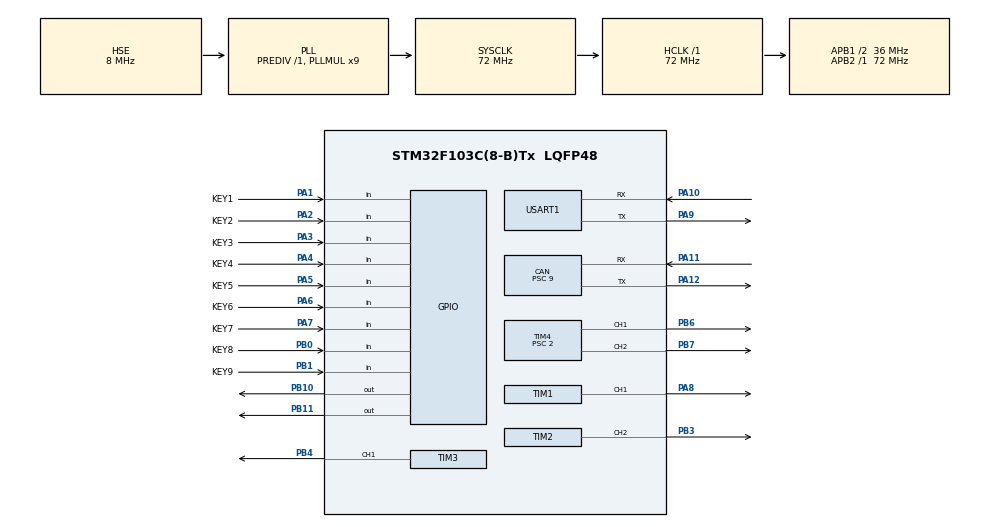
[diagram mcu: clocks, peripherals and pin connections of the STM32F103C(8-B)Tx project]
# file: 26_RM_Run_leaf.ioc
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CAN.BS2=CAN_BS2_2TQ
CAN.CalculateBaudRate=1000000
CAN.CalculateTimeBit=1000
CAN.CalculateTimeQuantum=250.0
CAN.Prescaler=9
Dma.Request0=TIM1_CH1
Dma.Request1=TIM2_CH2/CH4
Dma.Request2=TIM4_CH1
Dma.Request3=TIM4_CH2
Dma.Request4=TIM3_CH1/TRIG
Dma.TIM1_CH1.0.Direction=DMA_MEMORY_TO_PERIPH
Dma.TIM1_CH1.0.Instance=DMA1_Channel2
Dma.TIM1_CH1.0.MemDataAlignment=DMA_MDATAALIGN_HALFWORD
Dma.TIM1_CH1.0.MemInc=DMA_MINC_ENABLE
Dma.TIM1_CH1.0.Mode=DMA_CIRCULAR
Dma.TIM1_CH1.0.PeriphDataAlignment=DMA_PDATAALIGN_HALFWORD
Dma.TIM1_CH1.0.PeriphInc=DMA_PINC_DISABLE
Dma.TIM1_CH1.0.Priority=DMA_PRIORITY_HIGH
Dma.TIM2_CH2/CH4.1.Direction=DMA_MEMORY_TO_PERIPH
Dma.TIM2_CH2/CH4.1.Instance=DMA1_Channel7
Dma.TIM2_CH2/CH4.1.MemDataAlignment=DMA_MDATAALIGN_HALFWORD
Dma.TIM2_CH2/CH4.1.MemInc=DMA_MINC_ENABLE
Dma.TIM2_CH2/CH4.1.Mode=DMA_CIRCULAR
Dma.TIM2_CH2/CH4.1.PeriphDataAlignment=DMA_PDATAALIGN_HALFWORD
Dma.TIM2_CH2/CH4.1.PeriphInc=DMA_PINC_DISABLE
Dma.TIM2_CH2/CH4.1.Priority=DMA_PRIORITY_HIGH
Dma.TIM3_CH1/TRIG.4.Direction=DMA_MEMORY_TO_PERIPH
Dma.TIM3_CH1/TRIG.4.Instance=DMA1_Channel6
Dma.TIM3_CH1/TRIG.4.MemDataAlignment=DMA_MDATAALIGN_HALFWORD
Dma.TIM3_CH1/TRIG.4.MemInc=DMA_MINC_ENABLE
Dma.TIM3_CH1/TRIG.4.Mode=DMA_CIRCULAR
Dma.TIM3_CH1/TRIG.4.PeriphDataAlignment=DMA_PDATAALIGN_HALFWORD
Dma.TIM3_CH1/TRIG.4.PeriphInc=DMA_PINC_DISABLE
Dma.TIM3_CH1/TRIG.4.Priority=DMA_PRIORITY_HIGH
Dma.TIM4_CH1.2.Direction=DMA_MEMORY_TO_PERIPH
Dma.TIM4_CH1.2.Instance=DMA1_Channel1
Dma.TIM4_CH1.2.MemDataAlignment=DMA_MDATAALIGN_HALFWORD
Dma.TIM4_CH1.2.MemInc=DMA_MINC_ENABLE
Dma.TIM4_CH1.2.Mode=DMA_CIRCULAR
Dma.TIM4_CH1.2.PeriphDataAlignment=DMA_PDATAALIGN_HALFWORD
Dma.TIM4_CH1.2.PeriphInc=DMA_PINC_DISABLE
Dma.TIM4_CH1.2.Priority=DMA_PRIORITY_HIGH
Dma.TIM4_CH2.3.Direction=DMA_MEMORY_TO_PERIPH
Dma.TIM4_CH2.3.Instance=DMA1_Channel4
Dma.TIM4_CH2.3.MemDataAlignment=DMA_MDATAALIGN_HALFWORD
Dma.TIM4_CH2.3.MemInc=DMA_MINC_ENABLE
Dma.TIM4_CH2.3.Mode=DMA_CIRCULAR
Dma.TIM4_CH2.3.PeriphDataAlignment=DMA_PDATAALIGN_HALFWORD
Dma.TIM4_CH2.3.PeriphInc=DMA_PINC_DISABLE
Dma.TIM4_CH2.3.Priority=DMA_PRIORITY_HIGH
Mcu.Family=STM32F1
Mcu.Name=STM32F103C(8-B)Tx
Mcu.Package=LQFP48
NVIC.DMA1_Channel1_IRQn=true\:0\:0\:false\:false\:true\:false\:true\:true
NVIC.DMA1_Channel2_IRQn=true\:0\:0\:false\:false\:true\:false\:true\:true
NVIC.DMA1_Channel4_IRQn=true\:0\:0\:false\:false\:true\:false\:true\:true
NVIC.DMA1_Channel6_IRQn=true\:0\:0\:false\:false\:true\:false\:true\:true
NVIC.DMA1_Channel7_IRQn=true\:0\:0\:false\:false\:true\:false\:true\:true
NVIC.PriorityGroup=NVIC_PRIORITYGROUP_4
PA1.GPIO_Label=KEY1
PA1.GPIO_PuPd=GPIO_PULLUP
PA1.Signal=GPIO_Input
PA10.Mode=Asynchronous
PA10.Signal=USART1_RX
PA11.Mode=CAN_Activate
PA11.Signal=CAN_RX
PA12.Mode=CAN_Activate
PA12.Signal=CAN_TX
PA13.Mode=Serial_Wire
PA13.Signal=SYS_JTMS-SWDIO
PA14.Mode=Serial_Wire
PA14.Signal=SYS_JTCK-SWCLK
PA2.GPIO_Label=KEY2
PA2.GPIO_PuPd=GPIO_PULLUP
PA2.Signal=GPIO_Input
PA3.GPIO_Label=KEY3
PA3.GPIO_PuPd=GPIO_PULLUP
PA3.Signal=GPIO_Input
PA4.GPIO_Label=KEY4
PA4.GPIO_PuPd=GPIO_PULLUP
PA4.Signal=GPIO_Input
PA5.GPIO_Label=KEY5
PA5.GPIO_PuPd=GPIO_PULLUP
PA5.Signal=GPIO_Input
PA6.GPIO_Label=KEY6
PA6.GPIO_PuPd=GPIO_PULLUP
PA6.Signal=GPIO_Input
PA7.GPIO_Label=KEY7
PA7.GPIO_PuPd=GPIO_PULLUP
PA7.Signal=GPIO_Input
PA8.Signal=S_TIM1_CH1
PA9.Mode=Asynchronous
PA9.Signal=USART1_TX
PB0.GPIO_Label=KEY8
PB0.GPIO_PuPd=GPIO_PULLUP
PB0.Signal=GPIO_Input
PB1.GPIO_Label=KEY9
PB1.GPIO_PuPd=GPIO_PULLUP
PB1.Signal=GPIO_Input
PB10.Signal=GPIO_Output
PB11.Signal=GPIO_Output
PB3.Signal=S_TIM2_CH2
PB4.Signal=S_TIM3_CH1
PB6.Signal=S_TIM4_CH1
PB7.Signal=S_TIM4_CH2
PD0-OSC_IN.Mode=HSE-External-Oscillator
PD0-OSC_IN.Signal=RCC_OSC_IN
PD1-OSC_OUT.Mode=HSE-External-Oscillator
PD1-OSC_OUT.Signal=RCC_OSC_OUT
ProjectManager.HeapSize=0x200
ProjectManager.StackSize=0x400
ProjectManager.TargetToolchain=STM32CubeIDE
RCC.AHBFreq_Value=72000000
RCC.APB1CLKDivider=RCC_HCLK_DIV2
RCC.APB1Freq_Value=36000000
RCC.APB1TimFreq_Value=72000000
RCC.APB2Freq_Value=72000000
RCC.APB2TimFreq_Value=72000000
RCC.HCLKFreq_Value=72000000
RCC.PLLMUL=RCC_PLL_MUL9
RCC.PLLSourceVirtual=RCC_PLLSOURCE_HSE
RCC.SYSCLKFreq_VALUE=72000000
RCC.SYSCLKSource=RCC_SYSCLKSOURCE_PLLCLK
RCC.USBFreq_Value=72000000
SH.S_TIM1_CH1.0=TIM1_CH1,PWM Generation1 CH1
SH.S_TIM2_CH2.0=TIM2_CH2,PWM Generation2 CH2
SH.S_TIM3_CH1.0=TIM3_CH1,PWM Generation1 CH1
SH.S_TIM4_CH1.0=TIM4_CH1,PWM Generation1 CH1
SH.S_TIM4_CH2.0=TIM4_CH2,PWM Generation2 CH2
TIM1.Channel-PWM\ Generation1\ CH1=TIM_CHANNEL_1
TIM1.Period=29
TIM1.Prescaler=2
TIM2.Channel-PWM\ Generation2\ CH2=TIM_CHANNEL_2
TIM2.Period=29
TIM2.Prescaler=2
TIM3.Channel-PWM\ Generation1\ CH1=TIM_CHANNEL_1
TIM3.Period=29
TIM3.Prescaler=2
TIM4.Channel-PWM\ Generation1\ CH1=TIM_CHANNEL_1
TIM4.Channel-PWM\ Generation2\ CH2=TIM_CHANNEL_2
TIM4.Period=29
TIM4.Prescaler=2
USART1.VirtualMode=VM_ASYNC
VP_TIM1_VS_ClockSourceINT.Mode=Internal
VP_TIM2_VS_ClockSourceINT.Mode=Internal
VP_TIM3_VS_ClockSourceINT.Mode=Internal
VP_TIM4_VS_ClockSourceINT.Mode=Internal
board=custom

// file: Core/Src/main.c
/* USER CODE BEGIN Header */
/**
  ******************************************************************************
  * @file           : main.c
  * @brief          : Main program body
  ******************************************************************************
  * @attention
  *
  * Copyright (c) 2026 STMicroelectronics.
  * All rights reserved.
  *
  * This software is licensed under terms that can be found in the LICENSE file
  * in the root directory of this software component.
  * If no LICENSE file comes with this software, it is provided AS-IS.
  *
  ******************************************************************************
  */
/* USER CODE END Header */
#include "main.h"
#include "can.h"
#include "dma.h"
#include "tim.h"
#include "usart.h"
#include "gpio.h"

/* USER CODE BEGIN Includes */
#include "deliver.h"
#include "light.h"

/* USER CODE END Includes */

void SystemClock_Config(void);

int main(void)
{

  /* MCU Configuration--------------------------------------------------------*/

  /* Reset of all peripherals, Initializes the Flash interface and the Systick. */
  HAL_Init();

  /* Configure the system clock */
  SystemClock_Config();

  /* Initialize all configured peripherals */
  MX_GPIO_Init();
  MX_DMA_Init();
  MX_TIM1_Init();
  MX_CAN_Init();
  MX_USART1_UART_Init();
  MX_TIM2_Init();
  MX_TIM4_Init();
  MX_TIM3_Init();
  /* USER CODE BEGIN 2 */
  can_filter_init(); // 初始化CAN过滤器
  Light_Init(RedState); // 初始化LED为红色阵营
  /* USER CODE END 2 */

  /* Infinite loop */
  /* USER CODE BEGIN WHILE */
  while (1)
  {
    led_update(); // 更新LED状态
    HAL_Delay(100); // 小延时，避免过于频繁更新
    /* USER CODE END WHILE */

  }
}

void SystemClock_Config(void)
{
  RCC_OscInitTypeDef RCC_OscInitStruct = {0};
  RCC_ClkInitTypeDef RCC_ClkInitStruct = {0};

  /** Initializes the RCC Oscillators according to the specified parameters
  * in the RCC_OscInitTypeDef structure.
  */
  RCC_OscInitStruct.OscillatorType = RCC_OSCILLATORTYPE_HSE;
  RCC_OscInitStruct.HSEState = RCC_HSE_ON;
  RCC_OscInitStruct.HSEPredivValue = RCC_HSE_PREDIV_DIV1;
  RCC_OscInitStruct.HSIState = RCC_HSI_ON;
  RCC_OscInitStruct.PLL.PLLState = RCC_PLL_ON;
  RCC_OscInitStruct.PLL.PLLSource = RCC_PLLSOURCE_HSE;
  RCC_OscInitStruct.PLL.PLLMUL = RCC_PLL_MUL9;
  if (HAL_RCC_OscConfig(&RCC_OscInitStruct) != HAL_OK)
  {
    Error_Handler();
  }

  /** Initializes the CPU, AHB and APB buses clocks
  */
  RCC_ClkInitStruct.ClockType = RCC_CLOCKTYPE_HCLK|RCC_CLOCKTYPE_SYSCLK
                              |RCC_CLOCKTYPE_PCLK1|RCC_CLOCKTYPE_PCLK2;
  RCC_ClkInitStruct.SYSCLKSource = RCC_SYSCLKSOURCE_PLLCLK;
  RCC_ClkInitStruct.AHBCLKDivider = RCC_SYSCLK_DIV1;
  RCC_ClkInitStruct.APB1CLKDivider = RCC_HCLK_DIV2;
  RCC_ClkInitStruct.APB2CLKDivider = RCC_HCLK_DIV1;

  if (HAL_RCC_ClockConfig(&RCC_ClkInitStruct, FLASH_LATENCY_2) != HAL_OK)
  {
    Error_Handler();
  }
}

void Error_Handler(void)
{
  __disable_irq();
  while (1)
  {
  }
}
